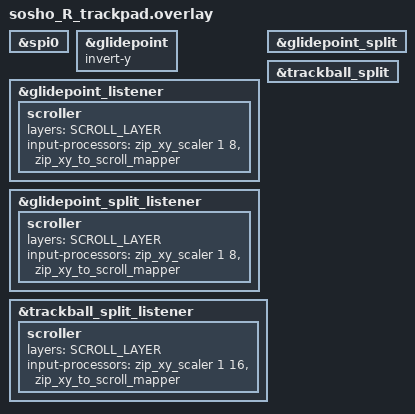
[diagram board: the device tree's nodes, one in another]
#include "sosho_R.dtsi"

/*
【スクロールモード】
keymap の scroll レイヤー(4番)がオンの間(L+; または A+S のコンボを押している間)だけ、
各リスナー内の scroller の input-processors が使われ、ポインタ移動の代わりにスクロールになります。
・&zip_xy_scaler 1 8 / 1 16 … スクロール速度。速すぎるなら分母を大きく、遅すぎるなら小さく。
*/
#define SCROLL_LAYER 4

/*
glidepoint_listnerは右手のトラックパッド
glidepoint_split_listenerとtrackball_split_listenerは
左手のトラックパッドとトラックボールの受けです。
ここにinput-processorというオプションをつけると、いろんな動きができます。
代表的なものを書いておきます。

・ポインタの移動を早くしたいとき
&zip_xy_scalerを使います。
分子 分母の順に数字を指定します。2 1なら2倍です。
input-processors = <&zip_xy_scaler 2 1>;

・スクロールを割り当てたいとき
zip_xy_to_scroll_mapperを使います。
ポインティングデバイスの動きをスクロールに変換してくれます。
input-processors = <&zip_xy_to_scroll_mapper>;

このオプションは複数併記することもできます。
input-processors = <&zip_xy_scaler 1 3>,<&zip_xy_to_scroll_mapper>;

詳しい情報はzmkのドキュメントを確認してください。
https://zmk.dev/docs/keymaps/input-processors
*/

&spi0 { status = "okay"; };
&glidepoint {
    status = "okay";
    invert-y;
};
&glidepoint_listener {
    status = "okay";
	//input-processors = <&zip_xy_scaler 2 1>;

	scroller {
		layers = <SCROLL_LAYER>;
		input-processors = <&zip_xy_scaler 1 8>, <&zip_xy_to_scroll_mapper>;
	};
};

&glidepoint_split { status = "okay"; };
&glidepoint_split_listener {
    status = "okay";

	scroller {
		layers = <SCROLL_LAYER>;
		input-processors = <&zip_xy_scaler 1 8>, <&zip_xy_to_scroll_mapper>;
	};
};

&trackball_split { status = "okay"; };
&trackball_split_listener {
	status = "okay";
	//input-processors = <&zip_xy_scaler 1 3>,<&zip_xy_to_scroll_mapper>;

	scroller {
		layers = <SCROLL_LAYER>;
		input-processors = <&zip_xy_scaler 1 16>, <&zip_xy_to_scroll_mapper>;
	};
};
